# CM41x_M0 register map
Vendor: Analog Devices; Series: CM41x_M0; File version: 1p0
CPU: CM0 r0p0, little endian, MPU, FPU, 4 interrupt priority bits
Registers are 32-bit, read-write, reset 0x0 unless marked. A register's access mark holds for its fields unless they carry their own. Offsets are from the block's base; [hi:lo] are bit positions; {n}, {i} and the like mark numbered series.

## FFTB0 — FFTB register map.
Base 0x40048000
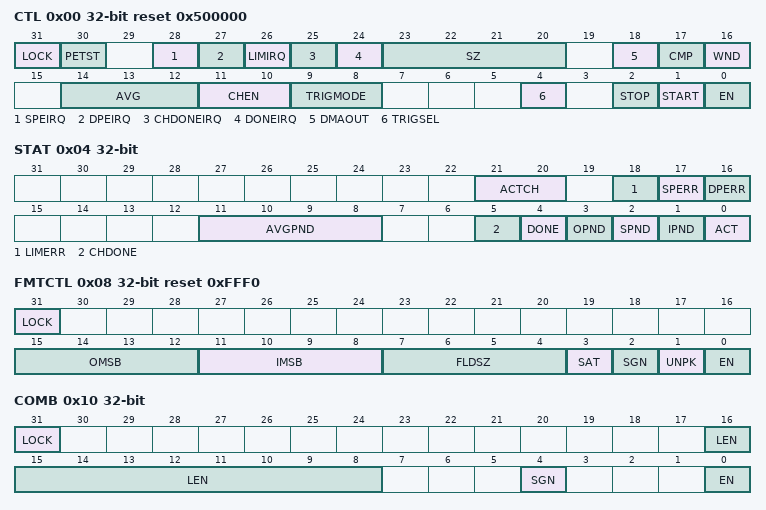
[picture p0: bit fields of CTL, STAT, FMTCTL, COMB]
0x00 CTL reset 0x500000 — FFTB Control Register
  [31] LOCK range 0x00000000..0x00000001 — Lock Enable
  [30] PETST range 0x00000000..0x00000001 — Enable Parity Test Mode
  [28] SPEIRQ range 0x00000000..0x00000001 — Setup Parity Error Interrupt Enable
  [27] DPEIRQ range 0x00000000..0x00000001 — Data Parity Error Interrupt Enable
  [26] LIMIRQ range 0x00000000..0x00000001 — Limit Interrupt Enable
  [25] CHDONEIRQ range 0x00000000..0x00000001 — Channel Done Interrupt Enable
  [24] DONEIRQ range 0x00000000..0x00000001 — Done Interrupt Enable
  [23:20] SZ — FFT Size
    5=FFTSZ_32 (The size of the input vector is 32 points.); 6=FFTSZ_64 (The size of the input vector is 64 points.); 7=FFTSZ_128 (The size of the input vector is 128 points.); 8=FFTSZ_256 (The size of the input vector is 256 points.); 9=FFTSZ_512 (The size of the input vector is 512 points.)
  [18] DMAOUT range 0x00000000..0x00000001 — DMA Output Enable
  [17] CMP range 0x00000000..0x00000001 — Compare enable
  [16] WND range 0x00000000..0x00000001 — Windowing Enable
  [14:12] AVG — Averaging Select
    0=NO_AVG (Spectrum averaging is disabled.); 1=Average the spectrum of 2 input vectors; 2=Average the spectrum of 4 input vectors; 3=Average the spectrum of 8 input vectors; 4=Average the spectrum of 16 input vectors
  [11:10] CHEN — Channel Enables
    0=CH0 (Channel 0 is enabled); 1=CH1 (Channel 0 and 1 are enabled); 2=CH2 (Channel 0, 1 and 2 are enabled); 3=CH3 (Channel 0, 1, 2 and 3 are enabled)
  [9:8] TRIGMODE — Triggering Mode
    0=MANUAL (Manual Triggering); 1=AUTO (Auto Triggering); 2=TRIG_ONE (Triggered One Shot (TRIG_ONE)); 3=TRIG_CONT (Triggered Continuous (TRIG_CONT))
  [4] TRIGSEL range 0x00000000..0x00000001 — Trigger Select Mask
  [2] STOP range 0x00000000..0x00000001 — FFT Stop
  [1] START range 0x00000000..0x00000001 — FFT Start
  [0] EN — FFT Enable
0x04 STAT — FFTB Status Register
  [21:20] ACTCH ro — Active Channel
    {v}=CHACT_{v} (Channel {v} active) (v=0..3)
  [18] LIMERR range 0x00000000..0x00000001 — Limit Error
  [17] SPERR range 0x00000000..0x00000001 — Setup Parity Error
  [16] DPERR range 0x00000000..0x00000001 — Data Parity Error
  [11:8] AVGPND ro — Averaging Pending
  [5] CHDONE range 0x00000000..0x00000001 — Channel Done
  [4] DONE range 0x00000000..0x00000001 — FFT done
  [3] OPND ro — DMA Output Pending
  [2] SPND ro — Spectrum Calculation Pending
  [1] IPND ro — Input Capture Pending
  [0] ACT ro — Active Status
0x08 FMTCTL reset 0xFFF0 — Format Converter Control Register
  [31] LOCK range 0x00000000..0x00000001 — Format Converter Lock Enable
  [15:12] OMSB range 0x00000000..0x0000000F — Output MSB
  [11:8] IMSB range 0x00000000..0x0000000F — Input MSB
  [7:4] FLDSZ range 0x00000000..0x0000000F — Field Size
  [3] SAT range 0x00000000..0x00000001 — Saturation Enable
  [2] SGN range 0x00000000..0x00000001 — Signed Input
  [1] UNPK range 0x00000000..0x00000001 — Unpack Input Stream
  [0] EN range 0x00000000..0x00000001 — Format Converter Enable
0x0C INOFST — Input Offset Register
  [15:0] VALUE range 0x00000000..0x0000FFFF — Input Offset
0x10 COMB — FFTB Input Comb Filter Control Register
  [31] LOCK range 0x00000000..0x00000001 — Comb Filter Lock Enable
  [16:8] LEN range 0x00000000..0x000001FF — Comb Filter Length
  [4] SGN range 0x00000000..0x00000001 — Comb Filter Sign
  [0] EN range 0x00000000..0x00000001 — Comb Filter Enable
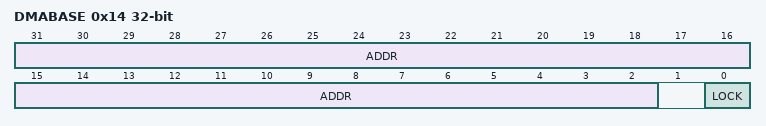
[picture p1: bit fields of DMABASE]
0x14 DMABASE — DMA Output Base Address Register
  [31:2] ADDR range 0x00000000..0x3FFFFFFF — DMA output base address
  [0] LOCK range 0x00000000..0x00000001 — DMA Address Lock Enable
0x18 DMAWR — DMA Output Write Address Register
  [31:0] ADDR ro — Current Address of DMA Output
{0x20+4i} MAGSEL[{i}] (i=0..8) reset 0xFFFFFFFF — Magnitude Pin Select Registers
  [31:0] VALUE range 0x00000000..0xFFFFFFFF — Magnitude Select
{0x70+4i} LIMSTAT[{i}] (i=0..8) — Limit Status Registers
  [31:0] VALUE ro — Over Limit Status
0xC0 MAXMAG — Maximum Magnitude Register
  [31:0] VALUE ro — Maximum magnitude square of the spectrum magnitude
0xC4 MINMAG — Minimum Magnitude Register
  [31:0] VALUE ro — Minimum magnitude square of the spectrum magnitude
